# MCXN236 register map
Vendor: nxp.com; File version: 1.0
CPU: CM33 r2p0, little endian, MPU, FPU, VTOR, 3 interrupt priority bits
Registers are 32-bit, read-write, reset 0x0 unless marked. A register's access mark holds for its fields unless they carry their own. Offsets are from the block's base; [hi:lo] are bit positions; lines under a group give offsets from that group; {n}, {i} and the like mark numbered series; 'fields as' and 'values as' point back to an identical list.

## EWM0 — EWM
Base 0x400C0000
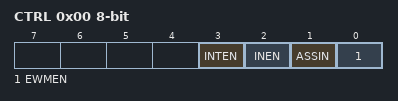
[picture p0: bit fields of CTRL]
0x00 CTRL 8-bit — Control
  [3] INTEN — Interrupt Enable
    0=ZERO (Deasserts interrupt requests); 1=INT_REQ (Generates interrupt requests)
  [2] INEN rw-once — Input Enable
    0=DISABLE (Disables); 1=ENABLE (Enables)
  [1] ASSIN rw-once — Assertion State Select
    0=DISABLE (Logic 0); 1=ENABLE (Logic 1)
  [0] EWMEN rw-once — EWM Enable
    0=DISABLE (Disables); 1=ENABLE (Enables)
0x01 SERV 8-bit — Service
  [7:0] SERVICE
0x02 CMPL 8-bit rw-once — Compare Low
  [7:0] COMPAREL
0x03 CMPH 8-bit rw-once reset 0xFF — Compare High
  [7:0] COMPAREH
0x04 CLKCTRL 8-bit rw-once — Clock Control
  [1:0] CLKSEL — Clock Select
0x05 CLKPRESCALER 8-bit rw-once — Clock Prescaler
  [7:0] CLK_DIV — Clock Divider

## CMX_PERFMON0 — CMX_PERFMON
Base 0x400C1000
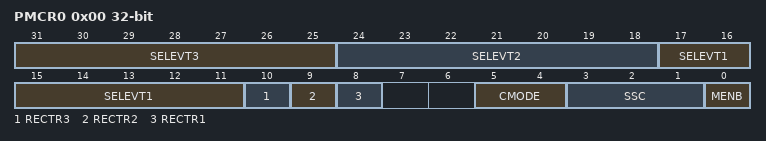
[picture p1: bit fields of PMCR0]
0x00 PMCR0 — Performance Monitor Control
  [31:25] SELEVT3 — Select Event 3
  [24:18] SELEVT2 — Select Event 2
  [17:11] SELEVT1 — Select Event 1
  [10] RECTR3 — Reset Event Counter 3
    0=RUN (Run normally); 1=RESET
  [9] RECTR2 — Reset Event Counter 2
    0=RUN (Run normally); 1=RESET
  [8] RECTR1 — Reset Event Counter 1
    0=RUN (Run normally); 1=RESET
  [5:4] CMODE — Count Mode
    0=USER_AND_PRIV (Counted in both User and Privileged modes); 2=USER_ONLY (Counted only in User mode); 3=PRIV_ONLY (Counted only in Privileged mode)
  [3:1] SSC — Start and Stop Control
    0=IDLE (Idle or no-op); 1=LSTOP (Local stop); 2=LSTART_2 (Local start); 3=LSTART_3 (Local start)
  [0] MENB ro — Module Is Enabled
    0=DISABLED; 1=ENABLED
{0x10+8i} PMECTR{i}_HI_0 8-bit ro (i=1..3) — Performance Monitor Event Counter
  [7:0] ECTR — Event Counter
{0x14+8i} PMECTR{i}_LO_0 ro (i=1..3) — Performance Monitor Event Counter
  [31:0] ECTR — Event Counter

## CRC0 — CRC
Base 0x400CB000
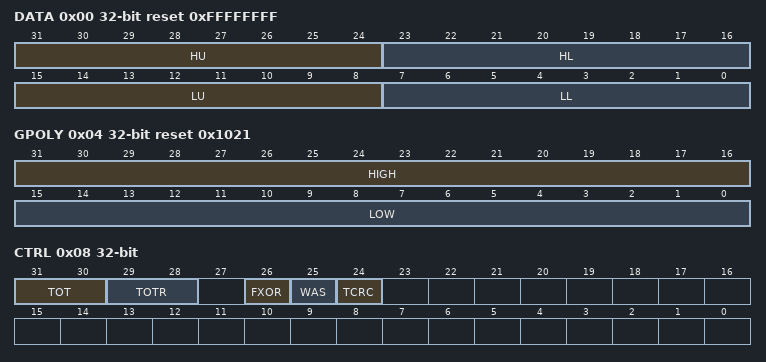
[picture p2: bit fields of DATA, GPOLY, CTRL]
0x00 DATA reset 0xFFFFFFFF — CRC Data
  [31:24] HU — CRC High Upper Byte
  [23:16] HL — CRC High Lower Byte
  [15:8] LU — CRC Low Upper Byte
  [7:0] LL — CRC Low Lower Byte
0x04 GPOLY reset 0x1021 — CRC Polynomial
  [31:16] HIGH — High Polynomial Half-Word
  [15:0] LOW — Low Polynomial Half-Word
0x08 CTRL — CRC Control
  [31:30] TOT — Transpose Type for Writes
    0=NOTRNPS (No transposition); 1=BTS_TRNPS (Bits in bytes are transposed; bytes are not transposed); 2=BYTS_BTS_TRNPS (Both bits in bytes and bytes are transposed); 3=BYTS_TRNPS (Only bytes are transposed; no bits in a byte are transposed)
  [29:28] TOTR — Transpose Type for Read
    values as TOT
  [26] FXOR — Complement Read of CRC Data Register
    0=NOXOR (No XOR on reading); 1=INVERT (Inverts or complements the read value of the CRC Data)
  [25] WAS — Write as Seed
    0=DATA (Data values); 1=SEED (Seed values)
  [24] TCRC
    0=B16 (16-bit); 1=B32 (32-bit)

## NPX0 — FMC
Base 0x400CC000
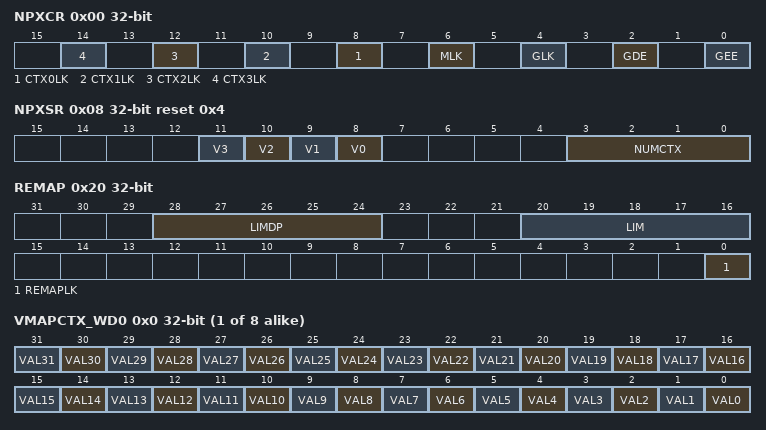
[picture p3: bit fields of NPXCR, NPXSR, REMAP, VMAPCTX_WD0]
0x00 NPXCR — NPX Control Register
  [2n+8] CTX{n}LK (n=0..3) — Lock Enable for Context {n}
    0=LOCK_DISABLED (Lock disabled: VMAPCTX{n} remains read-write); 1=LOCK_ENABLED (Lock enabled: cannot write to VMAPCTX{n} (becomes read-only))
  [6] MLK — Mask Lock Enable
    0=LOCK_DISABLED (Lock disabled. Subsequent reads return 0.); 1=LOCK_ENABLED (Lock enabled: cannot write to mask. Subsequent reads return 1.)
  [4] GLK — Global Lock Enable
    0=LOCK_DISABLED (Lock disabled. Subsequent reads return 0.); 1=LOCK_ENABLED (Lock enabled: cannot write to VMAPCTXn, NPXCR, or CACMSK. Subsequent reads return 1.)
  [2] GDE — Global Decryption Enable
    0=DECRYPTION_DISABLED (Global decryption disabled. NPX on-the-fly decryption is globally disabled. Subsequent reads return 0.); 1=DECRYPTION_ENABLED (Global decryption enabled. NPX on-the-fly decryption is globally enabled. Subsequent reads return 1.)
  [0] GEE — Global Encryption Enable
    0=ENCRYPTION_DISABLED (Global encryption disabled. NPX on-the-fly encryption is disabled. Subsequent reads return 0.); 1=ENCRYPTION_ENABLED (Global encryption enabled. NPX on-the-fly encryption is enabled if the flash access hits in a valid memory context. Subsequent reads return 1.)
0x08 NPXSR ro reset 0x4 — NPX Status Register
  [n+8] V{n} (n=0..3) — Key n Valid
    0=KEY_NOTVALID (Not valid); 1=KEY_VALID (Valid)
  [3:0] NUMCTX — Number of implemented memory contexts
    0=ZERO_CTX (No (zero) implemented memory contexts); 1=ONE_CTX (1 implemented memory contexts); 2=TWO_CTX (2 implemented memory contexts); 3=THREE_CTX (3 implemented memory contexts); 4=FOUR_CTX (4 implemented memory contexts)
0x10 CACMSK wo — Flash Cache Obfuscation Mask
  [31:0] OBMASK — Obfuscation Mask
0x20 REMAP — Data Remap
  [28:24] LIMDP — LIM_DP data
  [20:16] LIM — LIM data
  [0] REMAPLK — Remap Lock Enable
    0=LOCK_DISABLED (Lock disabled: can write to REMAP); 1=LOCK_ENABLED (Lock enabled: cannot write to REMAP)
{0x40+0x10*i} CTX_VALID_IV_ARRAY[{i}] (i=0..3) group
  {0x0+4j} VMAPCTX_WD{j} (j=0..1) — Bitmap of Valid Control for Memory Context n
    [all] fields
      0=DISABLE; 1=ENABLE
    [n] VAL{n} (n=0..31) — Block valid enable for encryption/decryption
  {0x8+4j} BIVCTX_WD{j} (j=0..1) wo — Block Initial Vector for Memory Context n
    [31:0] BIV_WD0 — Block Initial Vector Word0
